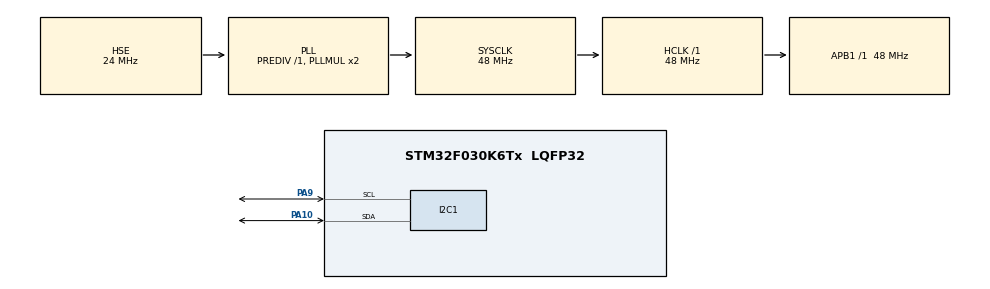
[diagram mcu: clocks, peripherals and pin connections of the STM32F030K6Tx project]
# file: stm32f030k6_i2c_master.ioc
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I2C1.Timing=0x2000090E
Mcu.Family=STM32F0
Mcu.Name=STM32F030K6Tx
Mcu.Package=LQFP32
PA10.Mode=I2C
PA10.Signal=I2C1_SDA
PA13.Mode=Serial-WireDebug
PA13.Signal=SYS_SWDIO
PA14.Mode=Serial-WireDebug
PA14.Signal=SYS_SWCLK
PA9.Mode=I2C
PA9.Signal=I2C1_SCL
PF0-OSC_IN.Mode=HSE-External-Oscillator
PF0-OSC_IN.Signal=RCC_OSC_IN
PF1-OSC_OUT.Mode=HSE-External-Oscillator
PF1-OSC_OUT.Signal=RCC_OSC_OUT
ProjectManager.TargetToolchain=MDK-ARM V5
RCC.AHBFreq_Value=48000000
RCC.APB1Freq_Value=48000000
RCC.APB1TimFreq_Value=48000000
RCC.HCLKFreq_Value=48000000
RCC.HSE_VALUE=24000000
RCC.PLLSourceVirtual=RCC_PLLSOURCE_HSE
RCC.SYSCLKFreq_VALUE=48000000
RCC.SYSCLKSource=RCC_SYSCLKSOURCE_PLLCLK
board=stm32f030k6_i2c_master

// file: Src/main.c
/**
  ******************************************************************************
  * File Name          : main.c
  * Description        : Main program body
  ******************************************************************************
  *
  * COPYRIGHT(c) 2016 STMicroelectronics
  *
  * Redistribution and use in source and binary forms, with or without modification,
  * are permitted provided that the following conditions are met:
  *   1. Redistributions of source code must retain the above copyright notice,
  *      this list of conditions and the following disclaimer.
  *   2. Redistributions in binary form must reproduce the above copyright notice,
  *      this list of conditions and the following disclaimer in the documentation
  *      and/or other materials provided with the distribution.
  *   3. Neither the name of STMicroelectronics nor the names of its contributors
  *      may be used to endorse or promote products derived from this software
  *      without specific prior written permission.
  *
  * THIS SOFTWARE IS PROVIDED BY THE COPYRIGHT HOLDERS AND CONTRIBUTORS "AS IS"
  * AND ANY EXPRESS OR IMPLIED WARRANTIES, INCLUDING, BUT NOT LIMITED TO, THE
  * IMPLIED WARRANTIES OF MERCHANTABILITY AND FITNESS FOR A PARTICULAR PURPOSE ARE
  * DISCLAIMED. IN NO EVENT SHALL THE COPYRIGHT HOLDER OR CONTRIBUTORS BE LIABLE
  * FOR ANY DIRECT, INDIRECT, INCIDENTAL, SPECIAL, EXEMPLARY, OR CONSEQUENTIAL
  * DAMAGES (INCLUDING, BUT NOT LIMITED TO, PROCUREMENT OF SUBSTITUTE GOODS OR
  * SERVICES; LOSS OF USE, DATA, OR PROFITS; OR BUSINESS INTERRUPTION) HOWEVER
  * CAUSED AND ON ANY THEORY OF LIABILITY, WHETHER IN CONTRACT, STRICT LIABILITY,
  * OR TORT (INCLUDING NEGLIGENCE OR OTHERWISE) ARISING IN ANY WAY OUT OF THE USE
  * OF THIS SOFTWARE, EVEN IF ADVISED OF THE POSSIBILITY OF SUCH DAMAGE.
  *
  ******************************************************************************
  */
#include "stm32f0xx_hal.h"
#include "i2c.h"
#include "gpio.h"

/* USER CODE BEGIN Includes */

#define MASTER_REQ_READ    0x12
#define MASTER_REQ_WRITE   0x34
/* Buffer used for transmission */
uint8_t aTxBuffer[] = " ****I2C_TwoBoards communication based on IT****  ****I2C_TwoBoards communication based on IT****  ****I2C_TwoBoards communication based on IT**** ";

/* Exported macro ------------------------------------------------------------*/
#define COUNTOF(__BUFFER__)   (sizeof(__BUFFER__) / sizeof(*(__BUFFER__)))

/* Size of Transmission buffer */
#define TXBUFFERSIZE                      (COUNTOF(aTxBuffer) - 1)
/* Size of Reception buffer */
#define RXBUFFERSIZE                      TXBUFFERSIZE
uint8_t aRxBuffer[RXBUFFERSIZE];
uint16_t hTxNumData = 0, hRxNumData = 0;
uint8_t bTransferRequest = 0;

/* USER CODE END Includes */

/* USER CODE BEGIN PV */
/* Private variables ---------------------------------------------------------*/

/* USER CODE END PV */

void SystemClock_Config(void);

/* USER CODE BEGIN PFP */
/* Private function prototypes -----------------------------------------------*/

/* USER CODE END PFP */

int main(void)
{

  /* MCU Configuration----------------------------------------------------------*/

  /* Reset of all peripherals, Initializes the Flash interface and the Systick. */
  HAL_Init();

  /* Configure the system clock */
  SystemClock_Config();

  /* Initialize all configured peripherals */
  MX_GPIO_Init();
  MX_I2C1_Init();

  /* Infinite loop */
  /* USER CODE BEGIN WHILE */
  while (1)
  {
		    /* Initialize number of data variables */
    hTxNumData = 0;
    hRxNumData = 0;

		    /*##-2- Slave receive request from master ################################*/
    while(HAL_I2C_Slave_Receive_IT(&hi2c1, (uint8_t*)&bTransferRequest, 1)!= HAL_OK)
    {
    }

    while (HAL_I2C_GetState(&hi2c1) != HAL_I2C_STATE_READY)
    {
    }

		  /* If master request write operation #####################################*/
    if (bTransferRequest == MASTER_REQ_WRITE)
    {
      /*##-3- Slave receive number of data to be read ########################*/
      while(HAL_I2C_Slave_Receive_IT(&hi2c1, (uint8_t*)&hRxNumData, 2)!= HAL_OK);

      while (HAL_I2C_GetState(&hi2c1) != HAL_I2C_STATE_READY)
      {
      }

		 /*##-4- Slave receives aRxBuffer from master ###########################*/
      while(HAL_I2C_Slave_Receive_IT(&hi2c1, (uint8_t*)aRxBuffer, hRxNumData)!= HAL_OK);

      while (HAL_I2C_GetState(&hi2c1) != HAL_I2C_STATE_READY)
      {
      }
		}
		else
    {
      /*##-3- Slave receive number of data to be written #####################*/
      while(HAL_I2C_Slave_Receive_IT(&hi2c1, (uint8_t*)&hTxNumData, 2)!= HAL_OK);

      while (HAL_I2C_GetState(&hi2c1) != HAL_I2C_STATE_READY)
      {
      }

      /*##-4- Slave transmit aTxBuffer to master #############################*/
      while(HAL_I2C_Slave_Transmit_IT(&hi2c1, (uint8_t*)aTxBuffer, RXBUFFERSIZE)!= HAL_OK);

      while (HAL_I2C_GetState(&hi2c1) != HAL_I2C_STATE_READY)
      {
      }
    }

  /* USER CODE END WHILE */

  }

}

/** System Clock Configuration
*/
void SystemClock_Config(void)
{

  RCC_OscInitTypeDef RCC_OscInitStruct;
  RCC_ClkInitTypeDef RCC_ClkInitStruct;
  RCC_PeriphCLKInitTypeDef PeriphClkInit;

  RCC_OscInitStruct.OscillatorType = RCC_OSCILLATORTYPE_HSI|RCC_OSCILLATORTYPE_HSE;
  RCC_OscInitStruct.HSEState = RCC_HSE_ON;
  RCC_OscInitStruct.HSIState = RCC_HSI_ON;
  RCC_OscInitStruct.HSICalibrationValue = 16;
  RCC_OscInitStruct.PLL.PLLState = RCC_PLL_ON;
  RCC_OscInitStruct.PLL.PLLSource = RCC_PLLSOURCE_HSE;
  RCC_OscInitStruct.PLL.PLLMUL = RCC_PLL_MUL2;
  RCC_OscInitStruct.PLL.PREDIV = RCC_PREDIV_DIV1;
  HAL_RCC_OscConfig(&RCC_OscInitStruct);

  RCC_ClkInitStruct.ClockType = RCC_CLOCKTYPE_SYSCLK;
  RCC_ClkInitStruct.SYSCLKSource = RCC_SYSCLKSOURCE_PLLCLK;
  RCC_ClkInitStruct.AHBCLKDivider = RCC_SYSCLK_DIV1;
  RCC_ClkInitStruct.APB1CLKDivider = RCC_HCLK_DIV1;
  HAL_RCC_ClockConfig(&RCC_ClkInitStruct, FLASH_LATENCY_1);

  PeriphClkInit.PeriphClockSelection = RCC_PERIPHCLK_I2C1;
  PeriphClkInit.I2c1ClockSelection = RCC_I2C1CLKSOURCE_HSI;
  HAL_RCCEx_PeriphCLKConfig(&PeriphClkInit);

  HAL_SYSTICK_Config(HAL_RCC_GetHCLKFreq()/1000);

  HAL_SYSTICK_CLKSourceConfig(SYSTICK_CLKSOURCE_HCLK);

  /* SysTick_IRQn interrupt configuration */
  HAL_NVIC_SetPriority(SysTick_IRQn, 0, 0);
}

/************************ (C) COPYRIGHT STMicroelectronics *****END OF FILE****/
